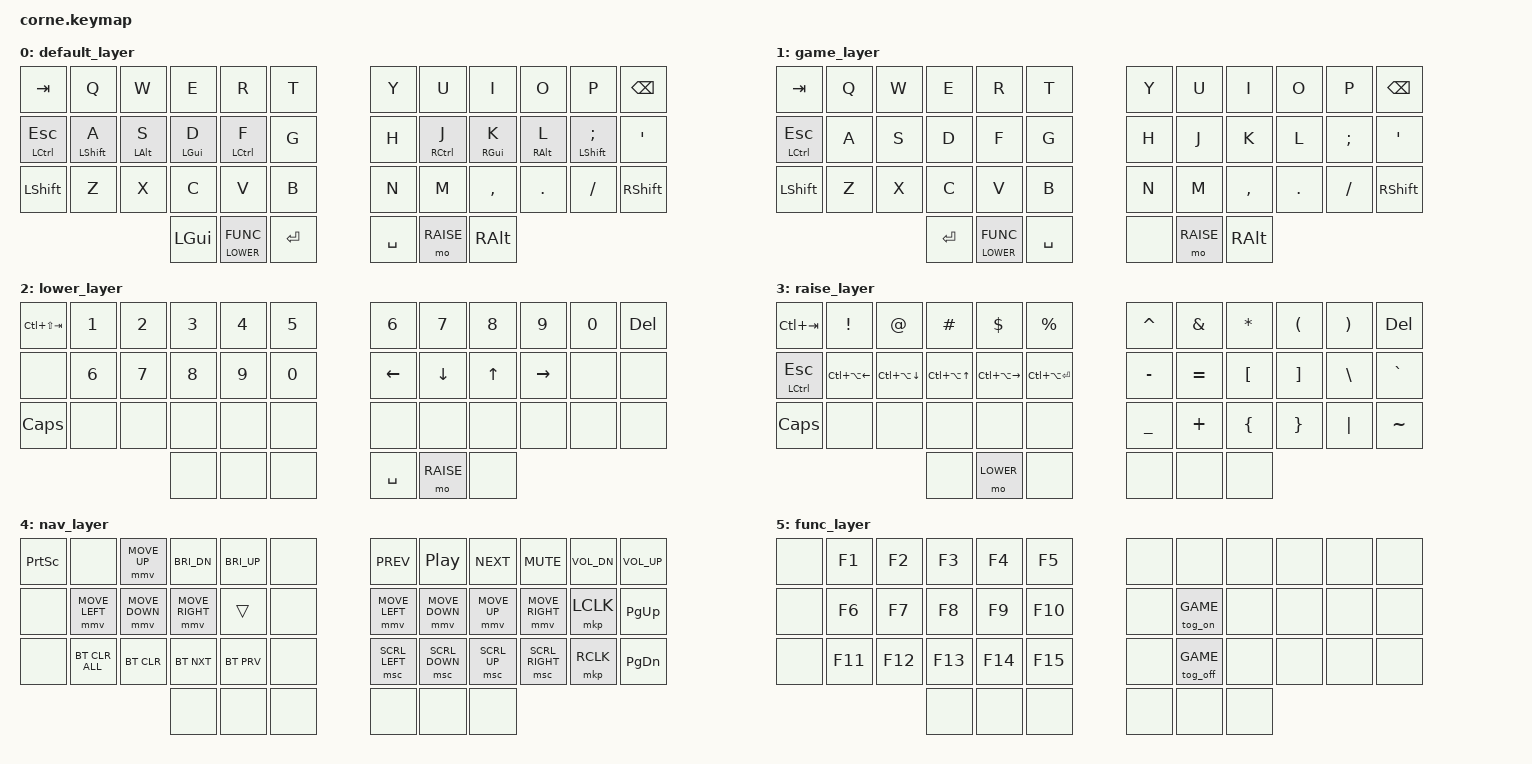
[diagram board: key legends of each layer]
/*
* Copyright (c) 2020 The ZMK Contributors
*
* SPDX-License-Identifier: MIT
*/

#define ZMK_POINTING_DEFAULT_MOVE_VAL 1500  // default: 600
#define ZMK_POINTING_DEFAULT_SCRL_VAL 30    // default: 10
#define KEYS_L 0 1 2 3 4 5 12 13 14 15 16 17 24 25 26 27 28 29 36 37 38
#define KEYS_R 6 7 8 9 10 11 18 19 20 21 22 23 30 31 32 33 34 35 39 40 41 42
#define GAME  1
#define LOWER 2
#define RAISE 3
#define NAV   4
#define FUNC  5

#include <dt-bindings/zmk/pointing.h>
#include <behaviors.dtsi>
#include <dt-bindings/zmk/keys.h>
#include <dt-bindings/zmk/bt.h>
#include <dt-bindings/zmk/pointing.h>

/ {
    conditional_layers {
        compatible = "zmk,conditional-layers";
        nav_layer {
            if-layers = <LOWER RAISE>;
            then-layer = <NAV>;
        };
    };
    behaviors {
        mo_sl: behavior_mo_sl {
            compatible = "zmk,behavior-hold-tap";
            #binding-cells = <2>;
            flavor = "hold-preferred";
            tapping-term-ms = <200>;
            bindings = <&mo>, <&sl>;
        };
        tog_on: toggle_layer_on_only {
            compatible = "zmk,behavior-toggle-layer";
            #binding-cells = <1>;
            display-name = "Toggle Layer On";
            toggle-mode = "on";
            locking;
        };
        tog_off: toggle_layer_off_only {
            compatible = "zmk,behavior-toggle-layer";
            #binding-cells = <1>;
            display-name = "Toggle Layer Off";
            toggle-mode = "off";
            locking;
        };
        hml: home_row_mod_left {
            compatible = "zmk,behavior-hold-tap";
            #binding-cells = <2>;
            flavor = "balanced";
            require-prior-idle-ms = <150>;
            tapping-term-ms = <280>;
            quick-tap-ms = <175>;
            bindings = <&kp>, <&kp>;
            hold-trigger-key-positions = < KEYS_R >;
            hold-trigger-on-release;
        };
        hmr: home_row_mod_right {
            compatible = "zmk,behavior-hold-tap";
            #binding-cells = <2>;
            flavor = "balanced";
            require-prior-idle-ms = <150>;
            tapping-term-ms = <280>;
            quick-tap-ms = <175>;
            bindings = <&kp>, <&kp>;
            hold-trigger-key-positions = < KEYS_L >;
            hold-trigger-on-release;
        };
    };
    keymap {
        compatible = "zmk,keymap";

        default_layer {
            // -----------------------------------------------------------------------------------------
            // | TAB  |  Q  |  W  |  E  |    R     |  T  |   |  Y  |  U   |  I  |  O  |  P  | BSPC |
            // | CTRL |  A  |  S  |  D  |    F     |  G  |   |  H  |  J   |  K  |  L  |  ;  |  '   |
            // | SHFT |  Z  |  X  |  C  |    V     |  B  |   |  N  |  M   |  ,  |  .  |  /  | SHFT |
            //                    | GUI | LWR/FUNC | ENT |   | SPC | RSE  | ALT |
            bindings = <
                &kp TAB       &kp Q        &kp W       &kp E             &kp R        &kp T     &kp Y     &kp U          &kp I          &kp O       &kp P           &kp BSPC
                &mt LCTRL ESC &hml LSHFT A &hml LALT S &hml LGUI D       &hml LCTRL F &kp G     &kp H     &hmr RCTRL J   &hmr RGUI K    &hmr RALT L &hmr LSHFT SEMI &kp SQT
                &kp LSHFT     &kp Z        &kp X       &kp C             &kp V        &kp B     &kp N     &kp M          &kp COMMA      &kp DOT     &kp FSLH        &kp RSHFT
                                           &kp LGUI    &mo_sl LOWER FUNC &kp RET      &kp SPACE &mo RAISE &kp RALT
            >;
        };
        game_layer {
            // -----------------------------------------------------------------------------------------
            // | TAB      |  Q  |  W  |    E    |     R    |  T  |    |  Y  |  U  |  I  |  O  |  P  | BSPC|
            // | CTRL/ESC |  A  |  S  |    D    |     F    |  G  |    |  H  |  J  |  K  |  L  |  ;  |  '  |
            // | SHFT     |  Z  |  X  |    C    |     V    |  B  |    |  N  |  M  |  ,  |  .  |     | SHFT|
            //                        | ENT/ALT | LWR/FUNC | SPC |    |     | RSE | ALT |
            bindings = <
                &kp TAB       &kp Q &kp W &kp E   &kp R             &kp T        &kp Y &kp U     &kp I     &kp O   &kp P    &kp BSPC
                &mt LCTRL ESC &kp A &kp S &kp D   &kp F             &kp G        &kp H &kp J     &kp K     &kp L   &kp SEMI &kp SQT
                &kp LSHFT     &kp Z &kp X &kp C   &kp V             &kp B        &kp N &kp M     &kp COMMA &kp DOT &kp FSLH &kp RSHFT
                                          &kp RET &mo_sl LOWER FUNC &kp SPACE    &none &mo RAISE &kp RALT
            >;
        };
        lower_layer {
            // -----------------------------------------------------------------------------------------
            // | CT+SF+TAB |  1  |  2  |  3  |  4  |  5  |    |  6  |  7  |  8  |  9  |  0  | DEL |
            // | CTRL/ESC  |  6  |  7  |  8  |  9  |  0  |    | LFT | DWN |  UP | RGT |     |     |
            // | CAPS      |     |     |     |     |     |    |     |     |     |  ,  |  .  |     |
            //                         |     |     |     |    |     |     |     |
            bindings = <
                &kp LC(LS(TAB)) &kp N1 &kp N2 &kp N3 &kp N4 &kp N5    &kp N6    &kp N7   &kp N8 &kp N9    &kp N0 &kp DEL
                &none           &kp N6 &kp N7 &kp N8 &kp N9 &kp N0    &kp LEFT  &kp DOWN &kp UP &kp RIGHT &none  &none
                &kp CAPS        &none  &none  &none  &none  &none     &none     &none    &none  &none     &none  &none
                                              &none  &none  &none     &kp SPACE &mo RAISE&none
            >;
        };

        raise_layer {
            // -----------------------------------------------------------------------------------------
            // | CT+TAB |  !   |  @   |  #   |  $   |  %   |    |  ^  |  &  |  *  |  (  |  )  | DEL |
            // | CTRL   | W-LF | W-DN | W-UP | W-RT | W-CN |    |  -  |  =  |  [  |  ]  |  \  |  `  |
            // | CAPS   |      |      |      |      |      |    |  _  |  +  |  {  |  }  | "|" |  ~  |
            //                        |      |      |      |    |     |     |     |
            bindings = <
                &kp LC(TAB)   &kp EXCL         &kp AT           &kp HASH       &kp DLLR          &kp PRCNT          &kp CARET &kp AMPS  &kp ASTRK &kp LPAR &kp RPAR &kp DEL
                &mt LCTRL ESC &kp LC(LA(LEFT)) &kp LC(LA(DOWN)) &kp LC(LA(UP)) &kp LC(LA(RIGHT)) &kp LC(LA(RET))    &kp MINUS &kp EQUAL &kp LBKT  &kp RBKT &kp BSLH &kp GRAVE
                &kp CAPS      &none            &none            &none          &none             &none              &kp UNDER &kp PLUS  &kp LBRC  &kp RBRC &kp PIPE &kp TILDE
                                                                &none          &mo LOWER         &none              &none     &none     &none
            >;
        };

        nav_layer {
            // -----------------------------------------------------------------------------------------
            // | SCRN |        | M-UP | S_DN   | S_UP   |   |    | PRV | PLY | NXT | MTE | V_DN | V_UP  |
            // |      | M-LF   | M-DN | M-RT   |        |   |    | M-LF| M-DN| M-UP| M-RT| LCLK | PG_UP |
            // |      | CLR_ALL| CLR  | BT_NXT | BT_PRV |   |    | S-LF| S-DN| S-UP| S-RT| RCLK | PG_DN |
            //                        |        |        |   |    |     |     |     |
            bindings = <
                &kp PSCRN &none           &mmv MOVE_UP   &kp C_BRI_DN    &kp C_BRI_UP &none    &kp C_PREV     &kp C_PP       &kp C_NEXT   &kp C_MUTE      &kp C_VOL_DN &kp C_VOL_UP
                &none     &mmv MOVE_LEFT  &mmv MOVE_DOWN &mmv MOVE_RIGHT &trans       &none    &mmv MOVE_LEFT &mmv MOVE_DOWN &mmv MOVE_UP &mmv MOVE_RIGHT &mkp LCLK    &kp PG_UP
                &none     &bt BT_CLR_ALL  &bt BT_CLR     &bt BT_NXT      &bt BT_PRV   &none    &msc SCRL_LEFT &msc SCRL_DOWN &msc SCRL_UP &msc SCRL_RIGHT &mkp RCLK    &kp PG_DN
                                                         &none           &none        &none    &none          &none          &none
            >;
        };

        func_layer {
            // -----------------------------------------------------------------------------------------
            // |      | F1  | F2  | F3  | F4  | F5  |    |     |     |     |     |     |     |
            // |      | F6  | F7  | F8  | F9  | F10 |    |     | GAME|     |     |     |     |
            // |      | F11 | F12 | F13 | F14 | F15 |    |     |     |     |     |     |     |
            //                    |     |     |     |    |     |     |     |
            bindings = <
                &none &kp F1  &kp F2  &kp F3  &kp F4  &kp F5     &none &none         &none &none &none &none
                &none &kp F6  &kp F7  &kp F8  &kp F9  &kp F10    &none &tog_on GAME  &none &none &none &none
                &none &kp F11 &kp F12 &kp F13 &kp F14 &kp F15    &none &tog_off GAME &none &none &none &none
                                      &none   &none   &none      &none &none         &none
            >;
        };
    };
};
